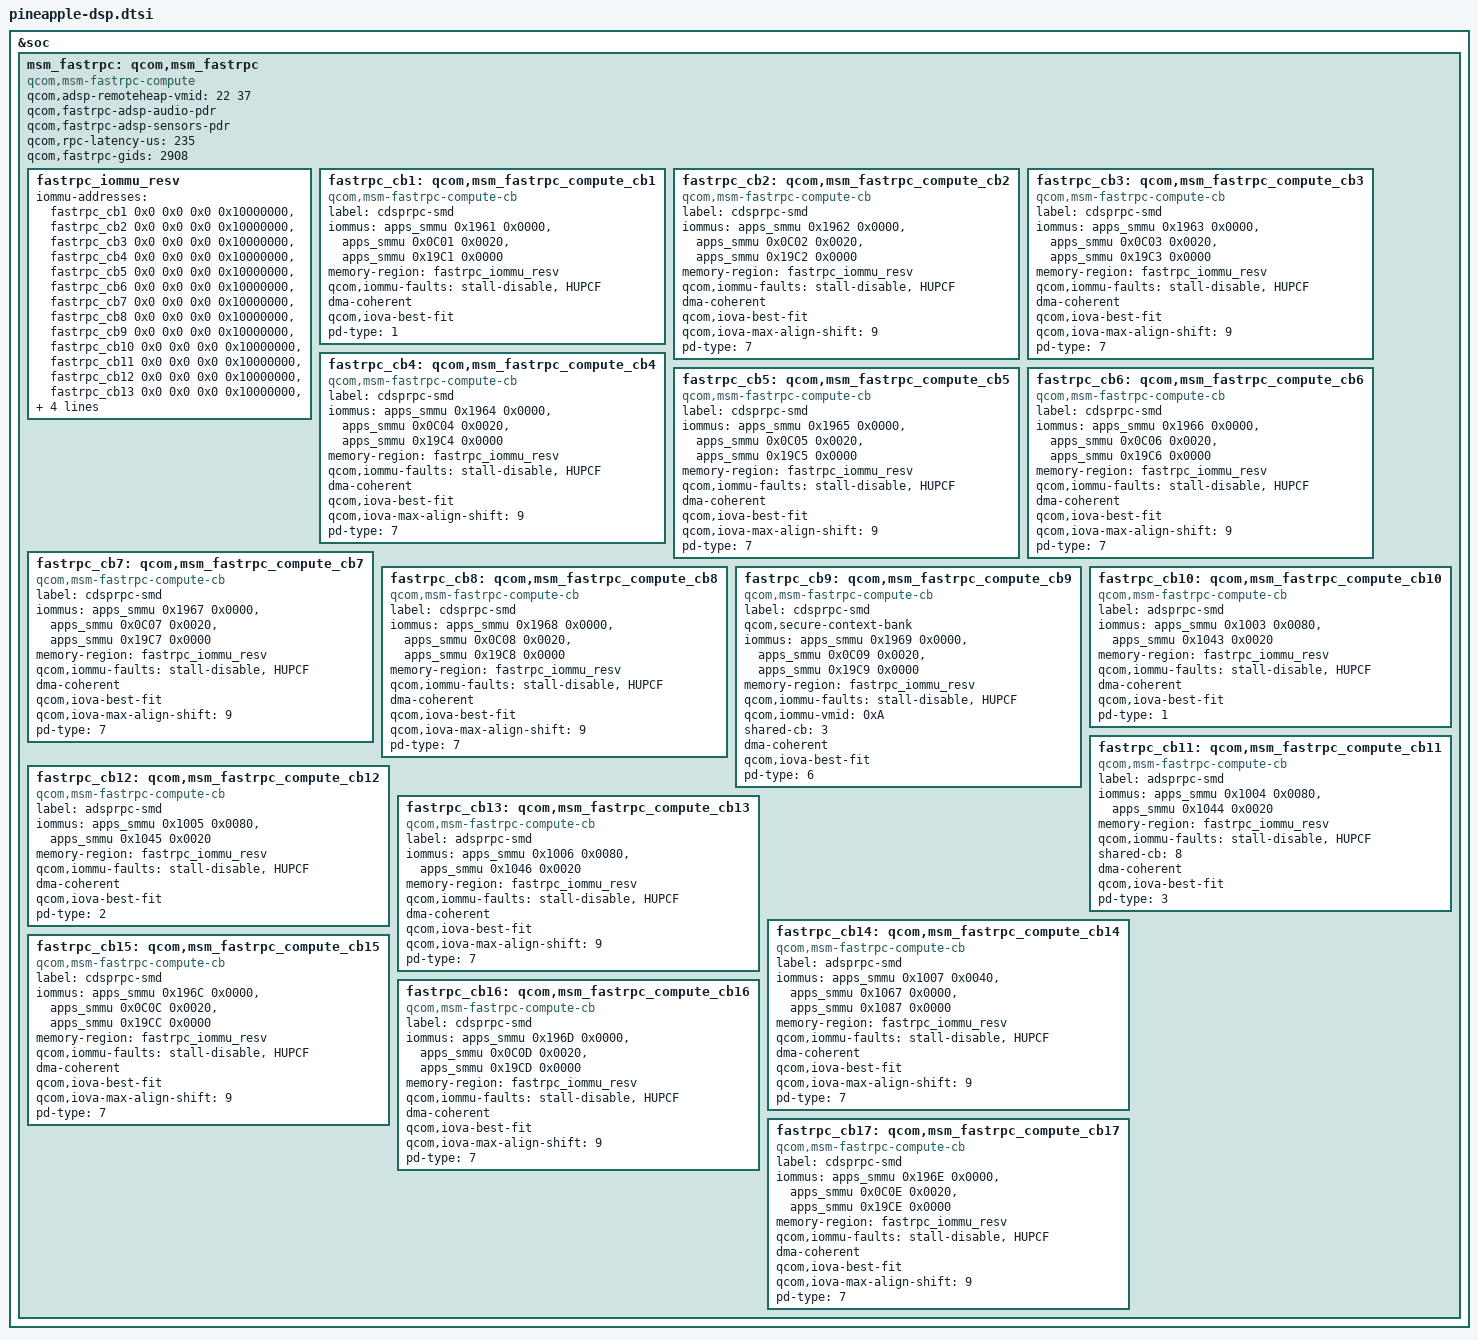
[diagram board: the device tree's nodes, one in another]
&soc {

	msm_fastrpc: qcom,msm_fastrpc {
		compatible = "qcom,msm-fastrpc-compute";
		qcom,adsp-remoteheap-vmid = <22 37>;
		qcom,fastrpc-adsp-audio-pdr;
		qcom,fastrpc-adsp-sensors-pdr;
		qcom,rpc-latency-us = <235>;
		qcom,fastrpc-gids = <2908>;

		#address-cells = <2>;
		#size-cells = <2>;

		fastrpc_iommu_resv: fastrpc_iommu_resv {
			iommu-addresses =
				<&fastrpc_cb1 0x0 0x0 0x0 0x10000000>,
				<&fastrpc_cb2 0x0 0x0 0x0 0x10000000>,
				<&fastrpc_cb3 0x0 0x0 0x0 0x10000000>,
				<&fastrpc_cb4 0x0 0x0 0x0 0x10000000>,
				<&fastrpc_cb5 0x0 0x0 0x0 0x10000000>,
				<&fastrpc_cb6 0x0 0x0 0x0 0x10000000>,
				<&fastrpc_cb7 0x0 0x0 0x0 0x10000000>,
				<&fastrpc_cb8 0x0 0x0 0x0 0x10000000>,
				<&fastrpc_cb9 0x0 0x0 0x0 0x10000000>,
				<&fastrpc_cb10 0x0 0x0 0x0 0x10000000>,
				<&fastrpc_cb11 0x0 0x0 0x0 0x10000000>,
				<&fastrpc_cb12 0x0 0x0 0x0 0x10000000>,
				<&fastrpc_cb13 0x0 0x0 0x0 0x10000000>,
				<&fastrpc_cb14 0x0 0x0 0x0 0x10000000>,
				<&fastrpc_cb15 0x0 0x0 0x0 0x10000000>,
				<&fastrpc_cb16 0x0 0x0 0x0 0x10000000>,
				<&fastrpc_cb17 0x0 0x0 0x0 0x10000000>;
		};

		fastrpc_cb1: qcom,msm_fastrpc_compute_cb1 {
			compatible = "qcom,msm-fastrpc-compute-cb";
			label = "cdsprpc-smd";
			iommus = <&apps_smmu 0x1961 0x0000>,
				 <&apps_smmu 0x0C01 0x0020>,
				 <&apps_smmu 0x19C1 0x0000>;
			memory-region = <&fastrpc_iommu_resv>;
			qcom,iommu-faults = "stall-disable", "HUPCF";
			dma-coherent;
			qcom,iova-best-fit;
			pd-type = <1>;	/* ROOT_PD */
		};

		fastrpc_cb2: qcom,msm_fastrpc_compute_cb2 {
			compatible = "qcom,msm-fastrpc-compute-cb";
			label = "cdsprpc-smd";
			iommus = <&apps_smmu 0x1962 0x0000>,
				 <&apps_smmu 0x0C02 0x0020>,
				 <&apps_smmu 0x19C2 0x0000>;
			memory-region = <&fastrpc_iommu_resv>;
			qcom,iommu-faults = "stall-disable", "HUPCF";
			dma-coherent;
			qcom,iova-best-fit;
			qcom,iova-max-align-shift = <9>; /* Set MAX alignment to 2 MB*/
			pd-type = <7>;	/* USERPD */
		};

		fastrpc_cb3: qcom,msm_fastrpc_compute_cb3 {
			compatible = "qcom,msm-fastrpc-compute-cb";
			label = "cdsprpc-smd";
			iommus = <&apps_smmu 0x1963 0x0000>,
				 <&apps_smmu 0x0C03 0x0020>,
				 <&apps_smmu 0x19C3 0x0000>;
			memory-region = <&fastrpc_iommu_resv>;
			qcom,iommu-faults = "stall-disable", "HUPCF";
			dma-coherent;
			qcom,iova-best-fit;
			qcom,iova-max-align-shift = <9>; /* Set MAX alignment to 2 MB*/
			pd-type = <7>;	/* USERPD */
		};

		fastrpc_cb4: qcom,msm_fastrpc_compute_cb4 {
			compatible = "qcom,msm-fastrpc-compute-cb";
			label = "cdsprpc-smd";
			iommus = <&apps_smmu 0x1964 0x0000>,
				 <&apps_smmu 0x0C04 0x0020>,
				 <&apps_smmu 0x19C4 0x0000>;
			memory-region = <&fastrpc_iommu_resv>;
			qcom,iommu-faults = "stall-disable", "HUPCF";
			dma-coherent;
			qcom,iova-best-fit;
			qcom,iova-max-align-shift = <9>; /* Set MAX alignment to 2 MB*/
			pd-type = <7>;	/* USERPD */
		};

		fastrpc_cb5: qcom,msm_fastrpc_compute_cb5 {
			compatible = "qcom,msm-fastrpc-compute-cb";
			label = "cdsprpc-smd";
			iommus = <&apps_smmu 0x1965 0x0000>,
				 <&apps_smmu 0x0C05 0x0020>,
				 <&apps_smmu 0x19C5 0x0000>;
			memory-region = <&fastrpc_iommu_resv>;
			qcom,iommu-faults = "stall-disable", "HUPCF";
			dma-coherent;
			qcom,iova-best-fit;
			qcom,iova-max-align-shift = <9>; /* Set MAX alignment to 2 MB*/
			pd-type = <7>;	/* USERPD */
		};

		fastrpc_cb6: qcom,msm_fastrpc_compute_cb6 {
			compatible = "qcom,msm-fastrpc-compute-cb";
			label = "cdsprpc-smd";
			iommus = <&apps_smmu 0x1966 0x0000>,
				 <&apps_smmu 0x0C06 0x0020>,
				 <&apps_smmu 0x19C6 0x0000>;
			memory-region = <&fastrpc_iommu_resv>;
			qcom,iommu-faults = "stall-disable", "HUPCF";
			dma-coherent;
			qcom,iova-best-fit;
			qcom,iova-max-align-shift = <9>; /* Set MAX alignment to 2 MB*/
			pd-type = <7>;	/* USERPD */
		};

		fastrpc_cb7: qcom,msm_fastrpc_compute_cb7 {
			compatible = "qcom,msm-fastrpc-compute-cb";
			label = "cdsprpc-smd";
			iommus = <&apps_smmu 0x1967 0x0000>,
				 <&apps_smmu 0x0C07 0x0020>,
				 <&apps_smmu 0x19C7 0x0000>;
			memory-region = <&fastrpc_iommu_resv>;
			qcom,iommu-faults = "stall-disable", "HUPCF";
			dma-coherent;
			qcom,iova-best-fit;
			qcom,iova-max-align-shift = <9>; /* Set MAX alignment to 2 MB*/
			pd-type = <7>;	/* USERPD */
		};

		fastrpc_cb8: qcom,msm_fastrpc_compute_cb8 {
			compatible = "qcom,msm-fastrpc-compute-cb";
			label = "cdsprpc-smd";
			iommus = <&apps_smmu 0x1968 0x0000>,
				 <&apps_smmu 0x0C08 0x0020>,
				 <&apps_smmu 0x19C8 0x0000>;
			memory-region = <&fastrpc_iommu_resv>;
			qcom,iommu-faults = "stall-disable", "HUPCF";
			dma-coherent;
			qcom,iova-best-fit;
			qcom,iova-max-align-shift = <9>; /* Set MAX alignment to 2 MB*/
			pd-type = <7>;	/* USERPD */
		};

		fastrpc_cb9: qcom,msm_fastrpc_compute_cb9 {
			compatible = "qcom,msm-fastrpc-compute-cb";
			label = "cdsprpc-smd";
			qcom,secure-context-bank;
			iommus = <&apps_smmu 0x1969 0x0000>,
				 <&apps_smmu 0x0C09 0x0020>,
				 <&apps_smmu 0x19C9 0x0000>;
			memory-region = <&fastrpc_iommu_resv>;
			qcom,iommu-faults = "stall-disable", "HUPCF";
			qcom,iommu-vmid = <0xA>;	/* VMID_CP_PIXEL */
			shared-cb = <3>;
			dma-coherent;
			qcom,iova-best-fit;
			pd-type = <6>;	/* CPZ_USERPD */
		};

		fastrpc_cb10: qcom,msm_fastrpc_compute_cb10 {
			compatible = "qcom,msm-fastrpc-compute-cb";
			label = "adsprpc-smd";
			iommus = <&apps_smmu 0x1003 0x0080>,
				 <&apps_smmu 0x1043 0x0020>;
			memory-region = <&fastrpc_iommu_resv>;
			qcom,iommu-faults = "stall-disable", "HUPCF";
			dma-coherent;
			qcom,iova-best-fit;
			pd-type = <1>;	/* ROOT_PD */
		};

		fastrpc_cb11: qcom,msm_fastrpc_compute_cb11 {
			compatible = "qcom,msm-fastrpc-compute-cb";
			label = "adsprpc-smd";
			iommus = <&apps_smmu 0x1004 0x0080>,
				 <&apps_smmu 0x1044 0x0020>;
			memory-region = <&fastrpc_iommu_resv>;
			qcom,iommu-faults = "stall-disable", "HUPCF";
			shared-cb = <8>;
			dma-coherent;
			qcom,iova-best-fit;
			pd-type = <3>;	/* SENSORS_STATICPD */
		};

		fastrpc_cb12: qcom,msm_fastrpc_compute_cb12 {
			compatible = "qcom,msm-fastrpc-compute-cb";
			label = "adsprpc-smd";
			iommus = <&apps_smmu 0x1005 0x0080>,
				 <&apps_smmu 0x1045 0x0020>;
			memory-region = <&fastrpc_iommu_resv>;
			qcom,iommu-faults = "stall-disable", "HUPCF";
			dma-coherent;
			qcom,iova-best-fit;
			pd-type = <2>;	/* AUDIO_STATICPD */
		};

		fastrpc_cb13: qcom,msm_fastrpc_compute_cb13 {
			compatible = "qcom,msm-fastrpc-compute-cb";
			label = "adsprpc-smd";
			iommus = <&apps_smmu 0x1006 0x0080>,
				 <&apps_smmu 0x1046 0x0020>;
			memory-region = <&fastrpc_iommu_resv>;
			qcom,iommu-faults = "stall-disable", "HUPCF";
			dma-coherent;
			qcom,iova-best-fit;
			qcom,iova-max-align-shift = <9>; /* Set MAX alignment to 2 MB*/
			pd-type = <7>;	/* USERPD */
		};

		fastrpc_cb14: qcom,msm_fastrpc_compute_cb14 {
			compatible = "qcom,msm-fastrpc-compute-cb";
			label = "adsprpc-smd";
			iommus = <&apps_smmu 0x1007 0x0040>,
				 <&apps_smmu 0x1067 0x0000>,
				 <&apps_smmu 0x1087 0x0000>;
			memory-region = <&fastrpc_iommu_resv>;
			qcom,iommu-faults = "stall-disable", "HUPCF";
			dma-coherent;
			qcom,iova-best-fit;
			qcom,iova-max-align-shift = <9>; /* Set MAX alignment to 2 MB*/
			pd-type = <7>;	/* USERPD */
		};

		fastrpc_cb15: qcom,msm_fastrpc_compute_cb15 {
			compatible = "qcom,msm-fastrpc-compute-cb";
			label = "cdsprpc-smd";
			iommus = <&apps_smmu 0x196C 0x0000>,
				 <&apps_smmu 0x0C0C 0x0020>,
				 <&apps_smmu 0x19CC 0x0000>;
			memory-region = <&fastrpc_iommu_resv>;
			qcom,iommu-faults = "stall-disable", "HUPCF";
			dma-coherent;
			qcom,iova-best-fit;
			qcom,iova-max-align-shift = <9>; /* Set MAX alignment to 2 MB*/
			pd-type = <7>;	/* USERPD */
		};

		fastrpc_cb16: qcom,msm_fastrpc_compute_cb16 {
			compatible = "qcom,msm-fastrpc-compute-cb";
			label = "cdsprpc-smd";
			iommus = <&apps_smmu 0x196D 0x0000>,
				 <&apps_smmu 0x0C0D 0x0020>,
				 <&apps_smmu 0x19CD 0x0000>;
			memory-region = <&fastrpc_iommu_resv>;
			qcom,iommu-faults = "stall-disable", "HUPCF";
			dma-coherent;
			qcom,iova-best-fit;
			qcom,iova-max-align-shift = <9>; /* Set MAX alignment to 2 MB*/
			pd-type = <7>;	/* USERPD */
		};

		fastrpc_cb17: qcom,msm_fastrpc_compute_cb17 {
			compatible = "qcom,msm-fastrpc-compute-cb";
			label = "cdsprpc-smd";
			iommus = <&apps_smmu 0x196E 0x0000>,
				 <&apps_smmu 0x0C0E 0x0020>,
				 <&apps_smmu 0x19CE 0x0000>;
			memory-region = <&fastrpc_iommu_resv>;
			qcom,iommu-faults = "stall-disable", "HUPCF";
			dma-coherent;
			qcom,iova-best-fit;
			qcom,iova-max-align-shift = <9>; /* Set MAX alignment to 2 MB*/
			pd-type = <7>;	/* USERPD */
		};
	};
};
